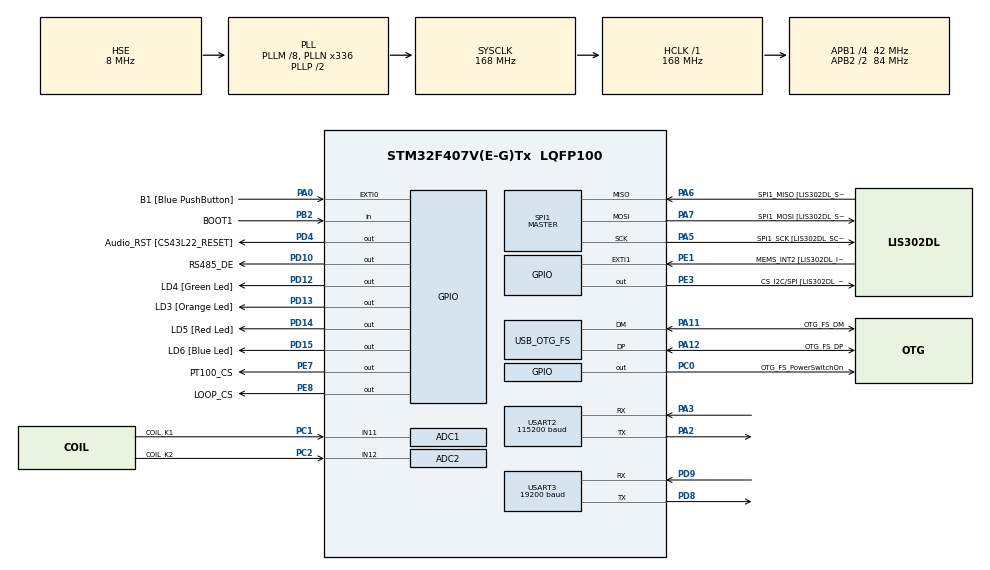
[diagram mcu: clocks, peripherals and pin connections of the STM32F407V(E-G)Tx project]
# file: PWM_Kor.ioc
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ADC1.Channel-0\#ChannelRegularConversion=ADC_CHANNEL_11
ADC1.ClockPrescaler=ADC_CLOCK_SYNC_PCLK_DIV4
ADC1.ContinuousConvMode=DISABLE
ADC1.DMAContinuousRequests=ENABLE
ADC1.EOCSelection=ADC_EOC_SEQ_CONV
ADC1.ExternalTrigConv=ADC_EXTERNALTRIGCONV_T2_TRGO
ADC1.ExternalTrigConvEdge=ADC_EXTERNALTRIGCONVEDGE_RISING
ADC1.Mode=ADC_DUALMODE_REGSIMULT
ADC1.NbrOfConversionFlag=1
ADC1.Rank-0\#ChannelRegularConversion=1
ADC1.SamplingTime-0\#ChannelRegularConversion=ADC_SAMPLETIME_144CYCLES
ADC1.master=1
ADC2.Channel-0\#ChannelRegularConversion=ADC_CHANNEL_12
ADC2.ContinuousConvMode=DISABLE
ADC2.DMAAccessMode=ADC_DMAACCESSMODE_2
ADC2.EOCSelection=ADC_EOC_SEQ_CONV
ADC2.Mode=ADC_DUALMODE_REGSIMULT
ADC2.NbrOfConversionFlag=1
ADC2.Rank-0\#ChannelRegularConversion=1
ADC2.SamplingTime-0\#ChannelRegularConversion=ADC_SAMPLETIME_144CYCLES
Dma.ADC1.0.Direction=DMA_PERIPH_TO_MEMORY
Dma.ADC1.0.FIFOMode=DMA_FIFOMODE_DISABLE
Dma.ADC1.0.Instance=DMA2_Stream0
Dma.ADC1.0.MemDataAlignment=DMA_MDATAALIGN_WORD
Dma.ADC1.0.MemInc=DMA_MINC_ENABLE
Dma.ADC1.0.Mode=DMA_CIRCULAR
Dma.ADC1.0.PeriphDataAlignment=DMA_PDATAALIGN_WORD
Dma.ADC1.0.PeriphInc=DMA_PINC_DISABLE
Dma.ADC1.0.Priority=DMA_PRIORITY_HIGH
Dma.Request0=ADC1
Dma.Request1=USART3_RX
Dma.Request2=USART3_TX
Dma.USART3_RX.1.Direction=DMA_PERIPH_TO_MEMORY
Dma.USART3_RX.1.FIFOMode=DMA_FIFOMODE_DISABLE
Dma.USART3_RX.1.Instance=DMA1_Stream1
Dma.USART3_RX.1.MemDataAlignment=DMA_MDATAALIGN_BYTE
Dma.USART3_RX.1.MemInc=DMA_MINC_ENABLE
Dma.USART3_RX.1.Mode=DMA_CIRCULAR
Dma.USART3_RX.1.PeriphDataAlignment=DMA_PDATAALIGN_BYTE
Dma.USART3_RX.1.PeriphInc=DMA_PINC_DISABLE
Dma.USART3_RX.1.Priority=DMA_PRIORITY_LOW
Dma.USART3_TX.2.Direction=DMA_MEMORY_TO_PERIPH
Dma.USART3_TX.2.FIFOMode=DMA_FIFOMODE_DISABLE
Dma.USART3_TX.2.Instance=DMA1_Stream3
Dma.USART3_TX.2.MemDataAlignment=DMA_MDATAALIGN_BYTE
Dma.USART3_TX.2.MemInc=DMA_MINC_ENABLE
Dma.USART3_TX.2.Mode=DMA_NORMAL
Dma.USART3_TX.2.PeriphDataAlignment=DMA_PDATAALIGN_BYTE
Dma.USART3_TX.2.PeriphInc=DMA_PINC_DISABLE
Dma.USART3_TX.2.Priority=DMA_PRIORITY_LOW
FREERTOS.Tasks01=defaultTask,24,128,StartDefaultTask,Default,NULL,Dynamic,NULL,NULL
FREERTOS.configCHECK_FOR_STACK_OVERFLOW=2
FREERTOS.configTOTAL_HEAP_SIZE=40000
Mcu.Family=STM32F4
Mcu.Name=STM32F407V(E-G)Tx
Mcu.Package=LQFP100
NVIC.DMA1_Stream1_IRQn=true\:5\:0\:false\:false\:true\:true\:false\:true\:true
NVIC.DMA1_Stream3_IRQn=true\:5\:0\:false\:false\:true\:true\:false\:true\:true
NVIC.DMA2_Stream0_IRQn=true\:5\:0\:false\:false\:true\:true\:true\:true\:true
NVIC.OTG_FS_IRQn=true\:5\:0\:false\:false\:true\:true\:true\:true\:true
NVIC.PriorityGroup=NVIC_PRIORITYGROUP_4
NVIC.TIM7_IRQn=true\:15\:0\:false\:false\:true\:false\:false\:true\:true
NVIC.TimeBase=TIM7_IRQn
NVIC.TimeBaseIP=TIM7
NVIC.USART3_IRQn=true\:5\:0\:true\:false\:true\:true\:true\:true\:true
PA0-WKUP.GPIO_Label=B1 [Blue PushButton]
PA0-WKUP.GPIO_ModeDefaultEXTI=GPIO_MODE_EVT_RISING
PA0-WKUP.GPIO_PuPd=GPIO_NOPULL
PA0-WKUP.Signal=GPXTI0
PA11.GPIO_Label=OTG_FS_DM
PA11.GPIO_Mode=GPIO_MODE_AF_PP
PA11.GPIO_PuPd=GPIO_NOPULL
PA11.GPIO_Speed=GPIO_SPEED_FREQ_LOW
PA11.Mode=Device_Only
PA11.Signal=USB_OTG_FS_DM
PA12.GPIO_Label=OTG_FS_DP
PA12.GPIO_Mode=GPIO_MODE_AF_PP
PA12.GPIO_PuPd=GPIO_NOPULL
PA12.GPIO_Speed=GPIO_SPEED_FREQ_LOW
PA12.Mode=Device_Only
PA12.Signal=USB_OTG_FS_DP
PA13.GPIO_Label=SWDIO
PA13.Mode=Serial_Wire
PA13.Signal=SYS_JTMS-SWDIO
PA14.GPIO_Label=SWCLK
PA14.Mode=Serial_Wire
PA14.Signal=SYS_JTCK-SWCLK
PA2.Mode=Asynchronous
PA2.Signal=USART2_TX
PA3.Mode=Asynchronous
PA3.Signal=USART2_RX
PA5.GPIO_Label=SPI1_SCK [LIS302DL_SCL/SPC]
PA5.GPIO_Mode=GPIO_MODE_AF_PP
PA5.GPIO_PuPd=GPIO_NOPULL
PA5.GPIO_Speed=GPIO_SPEED_FREQ_LOW
PA5.Mode=Full_Duplex_Master
PA5.Signal=SPI1_SCK
PA6.GPIO_Label=SPI1_MISO [LIS302DL_SDO]
PA6.GPIO_Mode=GPIO_MODE_AF_PP
PA6.GPIO_PuPd=GPIO_NOPULL
PA6.GPIO_Speed=GPIO_SPEED_FREQ_LOW
PA6.Mode=Full_Duplex_Master
PA6.Signal=SPI1_MISO
PA7.GPIO_Label=SPI1_MOSI [LIS302DL_SDA/SDI/SDO]
PA7.GPIO_Mode=GPIO_MODE_AF_PP
PA7.GPIO_PuPd=GPIO_NOPULL
PA7.GPIO_Speed=GPIO_SPEED_FREQ_LOW
PA7.Mode=Full_Duplex_Master
PA7.Signal=SPI1_MOSI
PB2.GPIO_Label=BOOT1
PB2.GPIO_Mode=GPIO_MODE_INPUT
PB2.GPIO_PuPd=GPIO_NOPULL
PB2.Signal=GPIO_Input
PB3.GPIO_Label=SWO
PB3.Signal=SYS_JTDO-SWO
PC0.GPIO_Label=OTG_FS_PowerSwitchOn
PC0.GPIO_PuPd=GPIO_NOPULL
PC0.GPIO_Speed=GPIO_SPEED_FREQ_LOW
PC0.PinState=GPIO_PIN_SET
PC0.Signal=GPIO_Output
PC1.GPIO_Label=COIL_K1
PC1.Signal=ADCx_IN11
PC14-OSC32_IN.GPIO_Label=PC14-OSC32_IN
PC14-OSC32_IN.Mode=LSE-External-Oscillator
PC14-OSC32_IN.Signal=RCC_OSC32_IN
PC15-OSC32_OUT.GPIO_Label=PC15-OSC32_OUT
PC15-OSC32_OUT.Mode=LSE-External-Oscillator
PC15-OSC32_OUT.Signal=RCC_OSC32_OUT
PC2.GPIO_Label=COIL_K2
PC2.Signal=ADCx_IN12
PD10.GPIO_Label=RS485_DE
PD10.Signal=GPIO_Output
PD12.GPIO_Label=LD4 [Green Led]
PD12.GPIO_PuPd=GPIO_NOPULL
PD12.GPIO_Speed=GPIO_SPEED_FREQ_LOW
PD12.Signal=GPIO_Output
PD13.GPIO_Label=LD3 [Orange Led]
PD13.GPIO_PuPd=GPIO_NOPULL
PD13.GPIO_Speed=GPIO_SPEED_FREQ_LOW
PD13.Signal=GPIO_Output
PD14.GPIO_Label=LD5 [Red Led]
PD14.GPIO_PuPd=GPIO_NOPULL
PD14.GPIO_Speed=GPIO_SPEED_FREQ_LOW
PD14.Signal=GPIO_Output
PD15.GPIO_Label=LD6 [Blue Led]
PD15.GPIO_PuPd=GPIO_NOPULL
PD15.GPIO_Speed=GPIO_SPEED_FREQ_LOW
PD15.Signal=GPIO_Output
PD4.GPIO_Label=Audio_RST [CS43L22_RESET]
PD4.GPIO_PuPd=GPIO_NOPULL
PD4.GPIO_Speed=GPIO_SPEED_FREQ_LOW
PD4.Signal=GPIO_Output
PD8.Mode=Asynchronous
PD8.Signal=USART3_TX
PD9.Mode=Asynchronous
PD9.Signal=USART3_RX
PE1.GPIO_Label=MEMS_INT2 [LIS302DL_INT2]
PE1.GPIO_ModeDefaultEXTI=GPIO_MODE_EVT_RISING
PE1.GPIO_PuPd=GPIO_NOPULL
PE1.Signal=GPXTI1
PE3.GPIO_Label=CS_I2C/SPI [LIS302DL_CS_I2C/SPI]
PE3.GPIO_PuPd=GPIO_NOPULL
PE3.GPIO_Speed=GPIO_SPEED_FREQ_LOW
PE3.PinState=GPIO_PIN_SET
PE3.Signal=GPIO_Output
PE7.GPIO_Label=PT100_CS
PE7.PinState=GPIO_PIN_SET
PE7.Signal=GPIO_Output
PE8.GPIO_Label=LOOP_CS
PE8.PinState=GPIO_PIN_SET
PE8.Signal=GPIO_Output
PH0-OSC_IN.GPIO_Label=PH0-OSC_IN
PH0-OSC_IN.Mode=HSE-External-Oscillator
PH0-OSC_IN.Signal=RCC_OSC_IN
PH1-OSC_OUT.GPIO_Label=PH1-OSC_OUT
PH1-OSC_OUT.Mode=HSE-External-Oscillator
PH1-OSC_OUT.Signal=RCC_OSC_OUT
ProjectManager.HeapSize=0x200
ProjectManager.StackSize=0x400
ProjectManager.TargetToolchain=STM32CubeIDE
RCC.48MHZClocksFreq_Value=48000000
RCC.AHBFreq_Value=168000000
RCC.APB1CLKDivider=RCC_HCLK_DIV4
RCC.APB1Freq_Value=42000000
RCC.APB1TimFreq_Value=84000000
RCC.APB2CLKDivider=RCC_HCLK_DIV2
RCC.APB2Freq_Value=84000000
RCC.APB2TimFreq_Value=168000000
RCC.CortexFreq_Value=168000000
RCC.HCLKFreq_Value=168000000
RCC.HSE_VALUE=8000000
RCC.HSI_VALUE=16000000
RCC.PLLM=8
RCC.PLLN=336
RCC.PLLQ=7
RCC.SYSCLKFreq_VALUE=168000000
RCC.SYSCLKSource=RCC_SYSCLKSOURCE_PLLCLK
RCC.VCOOutputFreq_Value=336000000
SH.ADCx_IN11.0=ADC1_IN11,IN11
SH.ADCx_IN12.0=ADC2_IN12,IN12
SPI1.BaudRatePrescaler-Full_Duplex_Master=SPI_BAUDRATEPRESCALER_2
SPI1.CalculateBaudRate-Full_Duplex_Master=42.0 MBits/s
SPI1.Direction=SPI_DIRECTION_2LINES
SPI1.Mode=SPI_MODE_MASTER
SPI1.Mode-Full_Duplex_Master=SPI_MODE_MASTER
SPI1.VirtualType=VM_MASTER
TIM2.Period=1049
TIM2.Prescaler=0
TIM2.TIM_MasterOutputTrigger=TIM_TRGO_UPDATE
USART2.BaudRate=115200
USART2.VirtualMode=VM_ASYNC
USART3.BaudRate=19200
USART3.VirtualMode=VM_ASYNC
USB_DEVICE.CLASS_NAME_FS=CDC
USB_DEVICE.VirtualMode-CDC_FS=Cdc
USB_DEVICE.VirtualModeFS=Cdc_FS
USB_OTG_FS.VirtualMode=Device_Only
VP_FREERTOS_VS_CMSIS_V2.Mode=CMSIS_V2
VP_SYS_VS_tim7.Mode=TIM7
VP_TIM2_VS_ClockSourceINT.Mode=Internal
VP_USB_DEVICE_VS_USB_DEVICE_CDC_FS.Mode=CDC_FS
board=STM32F407G-DISC1

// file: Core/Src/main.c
/* USER CODE BEGIN Header */
/**
  ******************************************************************************
  * @file           : main.c
  * @brief          : Main program body
  ******************************************************************************
  * @attention
  *
  * Copyright (c) 2026 STMicroelectronics.
  * All rights reserved.
  *
  * This software is licensed under terms that can be found in the LICENSE file
  * in the root directory of this software component.
  * If no LICENSE file comes with this software, it is provided AS-IS.
  *
  ******************************************************************************
  */
/* USER CODE END Header */
#include "main.h"
#include "cmsis_os.h"
#include "adc.h"
#include "dma.h"
#include "spi.h"
#include "tim.h"
#include "usart.h"
#include "usb_device.h"
#include "gpio.h"

void SystemClock_Config(void);
void MX_FREERTOS_Init(void);

int main(void)
{

  /* MCU Configuration--------------------------------------------------------*/

  /* Reset of all peripherals, Initializes the Flash interface and the Systick. */
  HAL_Init();

  /* Configure the system clock */
  SystemClock_Config();

  /* Initialize all configured peripherals */
  MX_GPIO_Init();
  MX_DMA_Init();
  MX_ADC1_Init();
  MX_ADC2_Init();
  MX_SPI1_Init();
  MX_TIM2_Init();
  MX_USART2_UART_Init();
  MX_USART3_UART_Init();

  /* Init scheduler */
  osKernelInitialize();  /* Call init function for freertos objects (in freertos.c) */
  MX_FREERTOS_Init();

  /* Start scheduler */
  osKernelStart();

  /* We should never get here as control is now taken by the scheduler */
  /* Infinite loop */
  while (1)
  {

  }
}

void SystemClock_Config(void)
{
  RCC_OscInitTypeDef RCC_OscInitStruct = {0};
  RCC_ClkInitTypeDef RCC_ClkInitStruct = {0};

  /** Configure the main internal regulator output voltage
  */
  __HAL_RCC_PWR_CLK_ENABLE();
  __HAL_PWR_VOLTAGESCALING_CONFIG(PWR_REGULATOR_VOLTAGE_SCALE1);

  /** Initializes the RCC Oscillators according to the specified parameters
  * in the RCC_OscInitTypeDef structure.
  */
  RCC_OscInitStruct.OscillatorType = RCC_OSCILLATORTYPE_HSE;
  RCC_OscInitStruct.HSEState = RCC_HSE_ON;
  RCC_OscInitStruct.PLL.PLLState = RCC_PLL_ON;
  RCC_OscInitStruct.PLL.PLLSource = RCC_PLLSOURCE_HSE;
  RCC_OscInitStruct.PLL.PLLM = 8;
  RCC_OscInitStruct.PLL.PLLN = 336;
  RCC_OscInitStruct.PLL.PLLP = RCC_PLLP_DIV2;
  RCC_OscInitStruct.PLL.PLLQ = 7;
  if (HAL_RCC_OscConfig(&RCC_OscInitStruct) != HAL_OK)
  {
    Error_Handler();
  }

  /** Initializes the CPU, AHB and APB buses clocks
  */
  RCC_ClkInitStruct.ClockType = RCC_CLOCKTYPE_HCLK|RCC_CLOCKTYPE_SYSCLK
                              |RCC_CLOCKTYPE_PCLK1|RCC_CLOCKTYPE_PCLK2;
  RCC_ClkInitStruct.SYSCLKSource = RCC_SYSCLKSOURCE_PLLCLK;
  RCC_ClkInitStruct.AHBCLKDivider = RCC_SYSCLK_DIV1;
  RCC_ClkInitStruct.APB1CLKDivider = RCC_HCLK_DIV4;
  RCC_ClkInitStruct.APB2CLKDivider = RCC_HCLK_DIV2;

  if (HAL_RCC_ClockConfig(&RCC_ClkInitStruct, FLASH_LATENCY_5) != HAL_OK)
  {
    Error_Handler();
  }
}

void HAL_TIM_PeriodElapsedCallback(TIM_HandleTypeDef *htim)
{
  if (htim->Instance == TIM7) {
    HAL_IncTick();
  }
}

void Error_Handler(void)
{
  __disable_irq();
  while (1)
  {
  }
}

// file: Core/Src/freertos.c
/* USER CODE BEGIN Header */
/**
  ******************************************************************************
  * File Name          : freertos.c
  * Description        : Code for freertos applications
  ******************************************************************************
  * @attention
  *
  * Copyright (c) 2026 STMicroelectronics.
  * All rights reserved.
  *
  * This software is licensed under terms that can be found in the LICENSE file
  * in the root directory of this software component.
  * If no LICENSE file comes with this software, it is provided AS-IS.
  *
  ******************************************************************************
  */
/* USER CODE END Header */

#include "FreeRTOS.h"
#include "task.h"
#include "main.h"
#include "cmsis_os.h"

/* USER CODE BEGIN Includes */
#include "coil.h"

/* USER CODE END Includes */

/* Definitions for defaultTask */
osThreadId_t defaultTaskHandle;
const osThreadAttr_t defaultTask_attributes = {
  .name = "defaultTask",
  .stack_size = 128 * 4,
  .priority = (osPriority_t) osPriorityNormal,
};

void StartDefaultTask(void *argument);

extern void MX_USB_DEVICE_Init(void);
void MX_FREERTOS_Init(void); /* (MISRA C 2004 rule 8.1) */

/* Hook prototypes */
void vApplicationStackOverflowHook(xTaskHandle xTask, signed char *pcTaskName);

/* USER CODE BEGIN 4 */
void vApplicationStackOverflowHook(xTaskHandle xTask, signed char *pcTaskName)
{
   /* Run time stack overflow checking is performed if
   configCHECK_FOR_STACK_OVERFLOW is defined to 1 or 2. This hook function is
   called if a stack overflow is detected. */
  // LD5 (красный) горит постоянно: стек задачи переполнен, имя задачи — в pcTaskName
  (void)xTask;
  (void)pcTaskName;
  taskDISABLE_INTERRUPTS();
  HAL_GPIO_WritePin(GPIOD, GPIO_PIN_14, GPIO_PIN_SET);
  for (;;)
  {
  }
}
/* USER CODE END 4 */

void MX_FREERTOS_Init(void) {

  /* Create the thread(s) */
  /* creation of defaultTask */
  defaultTaskHandle = osThreadNew(StartDefaultTask, NULL, &defaultTask_attributes);

  /* USER CODE BEGIN RTOS_THREADS */
  /* add threads, ... */
  Coil_Init();
  /* USER CODE END RTOS_THREADS */

}

void StartDefaultTask(void *argument)
{
  /* init code for USB_DEVICE */
  MX_USB_DEVICE_Init();
  /* USER CODE BEGIN StartDefaultTask */
  /* Infinite loop */
  for(;;)
  {
    // LD4 (зелёный) мигает 2 раза в секунду: планировщик и задача живы
    HAL_GPIO_TogglePin(GPIOD, GPIO_PIN_12);
    osDelay(250);
  }
  /* USER CODE END StartDefaultTask */
}
